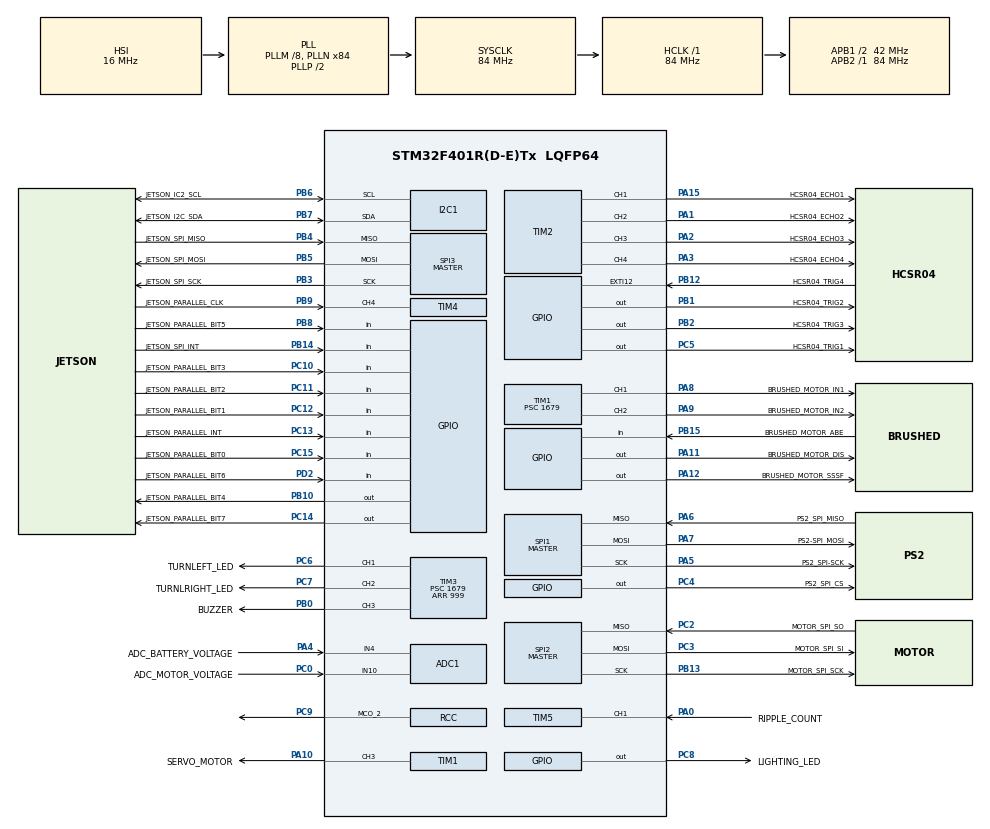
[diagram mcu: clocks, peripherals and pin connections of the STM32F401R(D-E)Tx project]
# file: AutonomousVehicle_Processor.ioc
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ADC1.Channel-0\#ChannelRegularConversion=ADC_CHANNEL_4
ADC1.NbrOfConversionFlag=1
ADC1.Rank-0\#ChannelRegularConversion=1
ADC1.SamplingTime-0\#ChannelRegularConversion=ADC_SAMPLETIME_3CYCLES
ADC1.master=1
FREERTOS.Tasks01=defaultTask,0,128,StartDefaultTask,Default,NULL,Dynamic,NULL,NULL
Mcu.Family=STM32F4
Mcu.Name=STM32F401R(D-E)Tx
Mcu.Package=LQFP64
NVIC.PriorityGroup=NVIC_PRIORITYGROUP_4
PA0-WKUP.GPIO_Label=RIPPLE_COUNT
PA0-WKUP.Signal=S_TIM5_CH1
PA1.GPIO_Label=HCSR04_ECHO2
PA1.Signal=S_TIM2_CH2
PA10.GPIO_Label=SERVO_MOTOR
PA10.Signal=S_TIM1_CH3
PA11.GPIO_Label=BRUSHED_MOTOR_DIS
PA11.Signal=GPIO_Output
PA12.GPIO_Label=BRUSHED_MOTOR_SSSF
PA12.Signal=GPIO_Output
PA13.Mode=Serial_Wire
PA13.Signal=SYS_JTMS-SWDIO
PA14.Mode=Serial_Wire
PA14.Signal=SYS_JTCK-SWCLK
PA15.GPIO_Label=HCSR04_ECHO1
PA15.Signal=S_TIM2_CH1_ETR
PA2.GPIO_Label=HCSR04_ECHO3
PA2.Signal=S_TIM2_CH3
PA3.GPIO_Label=HCSR04_ECHO4
PA3.Signal=S_TIM2_CH4
PA4.GPIO_Label=ADC_BATTERY_VOLTAGE
PA4.Signal=ADCx_IN4
PA5.GPIO_Label=PS2_SPI-SCK
PA5.Mode=Full_Duplex_Master
PA5.Signal=SPI1_SCK
PA6.GPIO_Label=PS2_SPI_MISO
PA6.Mode=Full_Duplex_Master
PA6.Signal=SPI1_MISO
PA7.GPIO_Label=PS2-SPI_MOSI
PA7.Mode=Full_Duplex_Master
PA7.Signal=SPI1_MOSI
PA8.GPIO_Label=BRUSHED_MOTOR_IN1
PA8.Signal=S_TIM1_CH1
PA9.GPIO_Label=BRUSHED_MOTOR_IN2
PA9.Signal=S_TIM1_CH2
PB0.GPIO_Label=BUZZER
PB0.Signal=S_TIM3_CH3
PB1.GPIO_Label=HCSR04_TRIG2
PB1.Signal=GPIO_Output
PB10.GPIO_Label=JETSON_PARALLEL_BIT4
PB10.Signal=GPIO_Output
PB12.GPIO_Label=HCSR04_TRIG4
PB12.Signal=GPXTI12
PB13.GPIO_Label=MOTOR_SPI_SCK
PB13.Mode=Full_Duplex_Master
PB13.Signal=SPI2_SCK
PB14.GPIO_Label=JETSON_SPI_INT
PB14.Signal=GPIO_Input
PB15.GPIO_Label=BRUSHED_MOTOR_ABE
PB15.Signal=GPIO_Input
PB2.GPIO_Label=HCSR04_TRIG3
PB2.Signal=GPIO_Output
PB3.GPIO_Label=JETSON_SPI_SCK
PB3.Mode=Full_Duplex_Master
PB3.Signal=SPI3_SCK
PB4.GPIO_Label=JETSON_SPI_MISO
PB4.Mode=Full_Duplex_Master
PB4.Signal=SPI3_MISO
PB5.GPIO_Label=JETSON_SPI_MOSI
PB5.Mode=Full_Duplex_Master
PB5.Signal=SPI3_MOSI
PB6.GPIO_Label=JETSON_IC2_SCL
PB6.Mode=I2C
PB6.Signal=I2C1_SCL
PB7.GPIO_Label=JETSON_I2C_SDA
PB7.Mode=I2C
PB7.Signal=I2C1_SDA
PB8.GPIO_Label=JETSON_PARALLEL_BIT5
PB8.Signal=GPIO_Input
PB9.GPIO_Label=JETSON_PARALLEL_CLK
PB9.Signal=S_TIM4_CH4
PC0.GPIO_Label=ADC_MOTOR_VOLTAGE
PC0.Signal=ADCx_IN10
PC10.GPIO_Label=JETSON_PARALLEL_BIT3
PC10.Signal=GPIO_Input
PC11.GPIO_Label=JETSON_PARALLEL_BIT2
PC11.Signal=GPIO_Input
PC12.GPIO_Label=JETSON_PARALLEL_BIT1
PC12.Signal=GPIO_Input
PC13-ANTI_TAMP.GPIO_Label=JETSON_PARALLEL_INT
PC13-ANTI_TAMP.Signal=GPIO_Input
PC14-OSC32_IN.GPIO_Label=JETSON_PARALLEL_BIT7
PC14-OSC32_IN.Signal=GPIO_Output
PC15-OSC32_OUT.GPIO_Label=JETSON_PARALLEL_BIT0
PC15-OSC32_OUT.Signal=GPIO_Input
PC2.GPIO_Label=MOTOR_SPI_SO
PC2.Mode=Full_Duplex_Master
PC2.Signal=SPI2_MISO
PC3.GPIO_Label=MOTOR_SPI_SI
PC3.Mode=Full_Duplex_Master
PC3.Signal=SPI2_MOSI
PC4.GPIO_Label=PS2_SPI_CS
PC4.Signal=GPIO_Output
PC5.GPIO_Label=HCSR04_TRIG1
PC5.Signal=GPIO_Output
PC6.GPIO_Label=TURNLEFT_LED
PC6.Signal=S_TIM3_CH1
PC7.GPIO_Label=TURNLRIGHT_LED
PC7.Signal=S_TIM3_CH2
PC8.GPIO_Label=LIGHTING_LED
PC8.Signal=GPIO_Output
PC9.Mode=Clock-out-2
PC9.Signal=RCC_MCO_2
PD2.GPIO_Label=JETSON_PARALLEL_BIT6
PD2.Signal=GPIO_Input
PH0\ -\ OSC_IN.Mode=HSE-External-Oscillator
PH0\ -\ OSC_IN.Signal=RCC_OSC_IN
PH1\ -\ OSC_OUT.Mode=HSE-External-Oscillator
PH1\ -\ OSC_OUT.Signal=RCC_OSC_OUT
ProjectManager.HeapSize=0x200
ProjectManager.StackSize=0x400
ProjectManager.TargetToolchain=STM32CubeIDE
RCC.48MHZClocksFreq_Value=42000000
RCC.AHBFreq_Value=84000000
RCC.APB1CLKDivider=RCC_HCLK_DIV2
RCC.APB1Freq_Value=42000000
RCC.APB1TimFreq_Value=84000000
RCC.APB2Freq_Value=84000000
RCC.APB2TimFreq_Value=84000000
RCC.CortexFreq_Value=84000000
RCC.HCLKFreq_Value=84000000
RCC.HSE_VALUE=25000000
RCC.HSI_VALUE=16000000
RCC.LSE_VALUE=32768
RCC.PLLM=8
RCC.PLLN=84
RCC.SYSCLKFreq_VALUE=84000000
RCC.SYSCLKSource=RCC_SYSCLKSOURCE_PLLCLK
RCC.VCOOutputFreq_Value=168000000
SH.ADCx_IN10.0=ADC1_IN10,IN10
SH.ADCx_IN4.0=ADC1_IN4,IN4
SH.S_TIM1_CH1.0=TIM1_CH1,PWM Generation1 CH1
SH.S_TIM1_CH2.0=TIM1_CH2,PWM Generation2 CH2
SH.S_TIM1_CH3.0=TIM1_CH3,PWM Generation3 CH3
SH.S_TIM2_CH1_ETR.0=TIM2_CH1,PWM Generation1 CH1
SH.S_TIM2_CH2.0=TIM2_CH2,PWM Generation2 CH2
SH.S_TIM2_CH3.0=TIM2_CH3,PWM Generation3 CH3
SH.S_TIM2_CH4.0=TIM2_CH4,PWM Generation4 CH4
SH.S_TIM3_CH1.0=TIM3_CH1,PWM Generation1 CH1
SH.S_TIM3_CH2.0=TIM3_CH2,PWM Generation2 CH2
SH.S_TIM3_CH3.0=TIM3_CH3,PWM Generation3 CH3
SH.S_TIM4_CH4.0=TIM4_CH4,Input_Capture4_from_TI4
SH.S_TIM5_CH1.0=TIM5_CH1,Input_Capture1_from_TI1
SPI1.Direction=SPI_DIRECTION_2LINES
SPI1.Mode=SPI_MODE_MASTER
SPI1.VirtualType=VM_MASTER
SPI2.Direction=SPI_DIRECTION_2LINES
SPI2.Mode=SPI_MODE_MASTER
SPI2.VirtualType=VM_MASTER
SPI3.Direction=SPI_DIRECTION_2LINES
SPI3.Mode=SPI_MODE_MASTER
SPI3.VirtualType=VM_MASTER
TIM1.Channel-PWM\ Generation1\ CH1=TIM_CHANNEL_1
TIM1.Channel-PWM\ Generation2\ CH2=TIM_CHANNEL_2
TIM1.Channel-PWM\ Generation3\ CH3=TIM_CHANNEL_3
TIM1.Period=999
TIM1.Prescaler=1679
TIM2.Channel-PWM\ Generation1\ CH1=TIM_CHANNEL_1
TIM2.Channel-PWM\ Generation2\ CH2=TIM_CHANNEL_2
TIM2.Channel-PWM\ Generation3\ CH3=TIM_CHANNEL_3
TIM2.Channel-PWM\ Generation4\ CH4=TIM_CHANNEL_4
TIM3.Channel-PWM\ Generation1\ CH1=TIM_CHANNEL_1
TIM3.Channel-PWM\ Generation2\ CH2=TIM_CHANNEL_2
TIM3.Channel-PWM\ Generation3\ CH3=TIM_CHANNEL_3
TIM3.Period=999
TIM3.Prescaler=1679
TIM4.Channel-Input_Capture4_from_TI4=TIM_CHANNEL_4
TIM5.Channel-Input_Capture1_from_TI1=TIM_CHANNEL_1
TIM5.Period=999
TIM5.Prescaler=1679
VP_FREERTOS_VS_CMSIS_V1.Mode=CMSIS_V1
board=custom

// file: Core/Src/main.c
/* USER CODE BEGIN Header */
/**
  ******************************************************************************
  * @file           : main.c
  * @brief          : Main program body
  ******************************************************************************
  * @attention
  *
  * Copyright (c) 2024 STMicroelectronics.
  * All rights reserved.
  *
  * This software is licensed under terms that can be found in the LICENSE file
  * in the root directory of this software component.
  * If no LICENSE file comes with this software, it is provided AS-IS.
  *
  ******************************************************************************
  */
/* USER CODE END Header */
#include "main.h"
#include "cmsis_os.h"

/* USER CODE BEGIN Includes */

// Drivers
#include "Auxiliary_System/Buzzer_System.h"
#include "Auxiliary_System/Lighting_System.h"
#include "Brushed_DC_Motor/Brushed_DC_Motor.h"
#include "Servo_Motor/Servo_Motor.h"
#include "Ripple_Current_Counter/Ripple_Current_Counter.h"
#include "Voltage_Measure/Voltage_Measure.h"

// Applications
#include "Auxiliary_Control/Auxiliary_Control.h"
#include "Brushed_Motor_Diagnosis/Motor_Diagnosis.h"
#include "Speeding_Control/Speeding_Control.h"
#include "Steering_Control/Steering_Control.h"
#include "PS2_Control/PS2_Control.h"
/* USER CODE END Includes */

ADC_HandleTypeDef hadc1;

I2C_HandleTypeDef hi2c1;

SPI_HandleTypeDef hspi1;
SPI_HandleTypeDef hspi2;
SPI_HandleTypeDef hspi3;

TIM_HandleTypeDef htim1;
TIM_HandleTypeDef htim2;
TIM_HandleTypeDef htim3;
TIM_HandleTypeDef htim4;
TIM_HandleTypeDef htim5;

osThreadId defaultTaskHandle;

void SystemClock_Config(void);
static void MX_GPIO_Init(void);
static void MX_ADC1_Init(void);
static void MX_SPI1_Init(void);
static void MX_SPI2_Init(void);
static void MX_TIM1_Init(void);
static void MX_TIM2_Init(void);
static void MX_TIM3_Init(void);
static void MX_TIM5_Init(void);
static void MX_TIM4_Init(void);
static void MX_I2C1_Init(void);
static void MX_SPI3_Init(void);
void StartDefaultTask(void const * argument);

int main(void)
{

  /* MCU Configuration--------------------------------------------------------*/

  /* Reset of all peripherals, Initializes the Flash interface and the Systick. */
  HAL_Init();

  /* Configure the system clock */
  SystemClock_Config();

  /* Initialize all configured peripherals */
  MX_GPIO_Init();
  MX_ADC1_Init();
  MX_SPI1_Init();
  MX_SPI2_Init();
  MX_TIM1_Init();
  MX_TIM2_Init();
  MX_TIM3_Init();
  MX_TIM5_Init();
  MX_TIM4_Init();
  MX_I2C1_Init();
  MX_SPI3_Init();

  /* Create the thread(s) */
  /* definition and creation of defaultTask */
  osThreadDef(defaultTask, StartDefaultTask, osPriorityNormal, 0, 128);
  defaultTaskHandle = osThreadCreate(osThread(defaultTask), NULL);

  /* Start scheduler */
  osKernelStart();

  /* We should never get here as control is now taken by the scheduler */
  /* Infinite loop */
  while (1)
  {

  }
}

void SystemClock_Config(void)
{
  RCC_OscInitTypeDef RCC_OscInitStruct = {0};
  RCC_ClkInitTypeDef RCC_ClkInitStruct = {0};

  /** Configure the main internal regulator output voltage
  */
  __HAL_RCC_PWR_CLK_ENABLE();
  __HAL_PWR_VOLTAGESCALING_CONFIG(PWR_REGULATOR_VOLTAGE_SCALE2);

  /** Initializes the RCC Oscillators according to the specified parameters
  * in the RCC_OscInitTypeDef structure.
  */
  RCC_OscInitStruct.OscillatorType = RCC_OSCILLATORTYPE_HSI;
  RCC_OscInitStruct.HSIState = RCC_HSI_ON;
  RCC_OscInitStruct.HSICalibrationValue = RCC_HSICALIBRATION_DEFAULT;
  RCC_OscInitStruct.PLL.PLLState = RCC_PLL_ON;
  RCC_OscInitStruct.PLL.PLLSource = RCC_PLLSOURCE_HSI;
  RCC_OscInitStruct.PLL.PLLM = 8;
  RCC_OscInitStruct.PLL.PLLN = 84;
  RCC_OscInitStruct.PLL.PLLP = RCC_PLLP_DIV2;
  RCC_OscInitStruct.PLL.PLLQ = 4;
  if (HAL_RCC_OscConfig(&RCC_OscInitStruct) != HAL_OK)
  {
    Error_Handler();
  }

  /** Initializes the CPU, AHB and APB buses clocks
  */
  RCC_ClkInitStruct.ClockType = RCC_CLOCKTYPE_HCLK|RCC_CLOCKTYPE_SYSCLK
                              |RCC_CLOCKTYPE_PCLK1|RCC_CLOCKTYPE_PCLK2;
  RCC_ClkInitStruct.SYSCLKSource = RCC_SYSCLKSOURCE_PLLCLK;
  RCC_ClkInitStruct.AHBCLKDivider = RCC_SYSCLK_DIV1;
  RCC_ClkInitStruct.APB1CLKDivider = RCC_HCLK_DIV2;
  RCC_ClkInitStruct.APB2CLKDivider = RCC_HCLK_DIV1;

  if (HAL_RCC_ClockConfig(&RCC_ClkInitStruct, FLASH_LATENCY_2) != HAL_OK)
  {
    Error_Handler();
  }
  HAL_RCC_MCOConfig(RCC_MCO2, RCC_MCO2SOURCE_SYSCLK, RCC_MCODIV_1);
}

static void MX_ADC1_Init(void)
{

  ADC_ChannelConfTypeDef sConfig = {0};

  /** Configure the global features of the ADC (Clock, Resolution, Data Alignment and number of conversion)
  */
  hadc1.Instance = ADC1;
  hadc1.Init.ClockPrescaler = ADC_CLOCK_SYNC_PCLK_DIV4;
  hadc1.Init.Resolution = ADC_RESOLUTION_12B;
  hadc1.Init.ScanConvMode = DISABLE;
  hadc1.Init.ContinuousConvMode = DISABLE;
  hadc1.Init.DiscontinuousConvMode = DISABLE;
  hadc1.Init.ExternalTrigConvEdge = ADC_EXTERNALTRIGCONVEDGE_NONE;
  hadc1.Init.ExternalTrigConv = ADC_SOFTWARE_START;
  hadc1.Init.DataAlign = ADC_DATAALIGN_RIGHT;
  hadc1.Init.NbrOfConversion = 1;
  hadc1.Init.DMAContinuousRequests = DISABLE;
  hadc1.Init.EOCSelection = ADC_EOC_SINGLE_CONV;
  if (HAL_ADC_Init(&hadc1) != HAL_OK)
  {
    Error_Handler();
  }

  /** Configure for the selected ADC regular channel its corresponding rank in the sequencer and its sample time.
  */
  sConfig.Channel = ADC_CHANNEL_4;
  sConfig.Rank = 1;
  sConfig.SamplingTime = ADC_SAMPLETIME_3CYCLES;
  if (HAL_ADC_ConfigChannel(&hadc1, &sConfig) != HAL_OK)
  {
    Error_Handler();
  }

}

static void MX_I2C1_Init(void)
{

  hi2c1.Instance = I2C1;
  hi2c1.Init.ClockSpeed = 100000;
  hi2c1.Init.DutyCycle = I2C_DUTYCYCLE_2;
  hi2c1.Init.OwnAddress1 = 0;
  hi2c1.Init.AddressingMode = I2C_ADDRESSINGMODE_7BIT;
  hi2c1.Init.DualAddressMode = I2C_DUALADDRESS_DISABLE;
  hi2c1.Init.OwnAddress2 = 0;
  hi2c1.Init.GeneralCallMode = I2C_GENERALCALL_DISABLE;
  hi2c1.Init.NoStretchMode = I2C_NOSTRETCH_DISABLE;
  if (HAL_I2C_Init(&hi2c1) != HAL_OK)
  {
    Error_Handler();
  }

}

static void MX_SPI1_Init(void)
{

  /* SPI1 parameter configuration*/
  hspi1.Instance = SPI1;
  hspi1.Init.Mode = SPI_MODE_MASTER;
  hspi1.Init.Direction = SPI_DIRECTION_2LINES;
  hspi1.Init.DataSize = SPI_DATASIZE_8BIT;
  hspi1.Init.CLKPolarity = SPI_POLARITY_LOW;
  hspi1.Init.CLKPhase = SPI_PHASE_1EDGE;
  hspi1.Init.NSS = SPI_NSS_SOFT;
  hspi1.Init.BaudRatePrescaler = SPI_BAUDRATEPRESCALER_2;
  hspi1.Init.FirstBit = SPI_FIRSTBIT_MSB;
  hspi1.Init.TIMode = SPI_TIMODE_DISABLE;
  hspi1.Init.CRCCalculation = SPI_CRCCALCULATION_DISABLE;
  hspi1.Init.CRCPolynomial = 10;
  if (HAL_SPI_Init(&hspi1) != HAL_OK)
  {
    Error_Handler();
  }

}

static void MX_SPI2_Init(void)
{

  /* SPI2 parameter configuration*/
  hspi2.Instance = SPI2;
  hspi2.Init.Mode = SPI_MODE_MASTER;
  hspi2.Init.Direction = SPI_DIRECTION_2LINES;
  hspi2.Init.DataSize = SPI_DATASIZE_8BIT;
  hspi2.Init.CLKPolarity = SPI_POLARITY_LOW;
  hspi2.Init.CLKPhase = SPI_PHASE_1EDGE;
  hspi2.Init.NSS = SPI_NSS_SOFT;
  hspi2.Init.BaudRatePrescaler = SPI_BAUDRATEPRESCALER_2;
  hspi2.Init.FirstBit = SPI_FIRSTBIT_MSB;
  hspi2.Init.TIMode = SPI_TIMODE_DISABLE;
  hspi2.Init.CRCCalculation = SPI_CRCCALCULATION_DISABLE;
  hspi2.Init.CRCPolynomial = 10;
  if (HAL_SPI_Init(&hspi2) != HAL_OK)
  {
    Error_Handler();
  }

}

static void MX_SPI3_Init(void)
{

  /* SPI3 parameter configuration*/
  hspi3.Instance = SPI3;
  hspi3.Init.Mode = SPI_MODE_MASTER;
  hspi3.Init.Direction = SPI_DIRECTION_2LINES;
  hspi3.Init.DataSize = SPI_DATASIZE_8BIT;
  hspi3.Init.CLKPolarity = SPI_POLARITY_LOW;
  hspi3.Init.CLKPhase = SPI_PHASE_1EDGE;
  hspi3.Init.NSS = SPI_NSS_SOFT;
  hspi3.Init.BaudRatePrescaler = SPI_BAUDRATEPRESCALER_2;
  hspi3.Init.FirstBit = SPI_FIRSTBIT_MSB;
  hspi3.Init.TIMode = SPI_TIMODE_DISABLE;
  hspi3.Init.CRCCalculation = SPI_CRCCALCULATION_DISABLE;
  hspi3.Init.CRCPolynomial = 10;
  if (HAL_SPI_Init(&hspi3) != HAL_OK)
  {
    Error_Handler();
  }

}

static void MX_TIM1_Init(void)
{

  TIM_MasterConfigTypeDef sMasterConfig = {0};
  TIM_OC_InitTypeDef sConfigOC = {0};
  TIM_BreakDeadTimeConfigTypeDef sBreakDeadTimeConfig = {0};

  htim1.Instance = TIM1;
  htim1.Init.Prescaler = 1679;
  htim1.Init.CounterMode = TIM_COUNTERMODE_UP;
  htim1.Init.Period = 999;
  htim1.Init.ClockDivision = TIM_CLOCKDIVISION_DIV1;
  htim1.Init.RepetitionCounter = 0;
  htim1.Init.AutoReloadPreload = TIM_AUTORELOAD_PRELOAD_DISABLE;
  if (HAL_TIM_PWM_Init(&htim1) != HAL_OK)
  {
    Error_Handler();
  }
  sMasterConfig.MasterOutputTrigger = TIM_TRGO_RESET;
  sMasterConfig.MasterSlaveMode = TIM_MASTERSLAVEMODE_DISABLE;
  if (HAL_TIMEx_MasterConfigSynchronization(&htim1, &sMasterConfig) != HAL_OK)
  {
    Error_Handler();
  }
  sConfigOC.OCMode = TIM_OCMODE_PWM1;
  sConfigOC.Pulse = 0;
  sConfigOC.OCPolarity = TIM_OCPOLARITY_HIGH;
  sConfigOC.OCNPolarity = TIM_OCNPOLARITY_HIGH;
  sConfigOC.OCFastMode = TIM_OCFAST_DISABLE;
  sConfigOC.OCIdleState = TIM_OCIDLESTATE_RESET;
  sConfigOC.OCNIdleState = TIM_OCNIDLESTATE_RESET;
  if (HAL_TIM_PWM_ConfigChannel(&htim1, &sConfigOC, TIM_CHANNEL_1) != HAL_OK)
  {
    Error_Handler();
  }
  if (HAL_TIM_PWM_ConfigChannel(&htim1, &sConfigOC, TIM_CHANNEL_2) != HAL_OK)
  {
    Error_Handler();
  }
  if (HAL_TIM_PWM_ConfigChannel(&htim1, &sConfigOC, TIM_CHANNEL_3) != HAL_OK)
  {
    Error_Handler();
  }
  sBreakDeadTimeConfig.OffStateRunMode = TIM_OSSR_DISABLE;
  sBreakDeadTimeConfig.OffStateIDLEMode = TIM_OSSI_DISABLE;
  sBreakDeadTimeConfig.LockLevel = TIM_LOCKLEVEL_OFF;
  sBreakDeadTimeConfig.DeadTime = 0;
  sBreakDeadTimeConfig.BreakState = TIM_BREAK_DISABLE;
  sBreakDeadTimeConfig.BreakPolarity = TIM_BREAKPOLARITY_HIGH;
  sBreakDeadTimeConfig.AutomaticOutput = TIM_AUTOMATICOUTPUT_DISABLE;
  if (HAL_TIMEx_ConfigBreakDeadTime(&htim1, &sBreakDeadTimeConfig) != HAL_OK)
  {
    Error_Handler();
  }
  HAL_TIM_MspPostInit(&htim1);

}

static void MX_TIM2_Init(void)
{

  TIM_MasterConfigTypeDef sMasterConfig = {0};
  TIM_OC_InitTypeDef sConfigOC = {0};

  htim2.Instance = TIM2;
  htim2.Init.Prescaler = 0;
  htim2.Init.CounterMode = TIM_COUNTERMODE_UP;
  htim2.Init.Period = 4294967295;
  htim2.Init.ClockDivision = TIM_CLOCKDIVISION_DIV1;
  htim2.Init.AutoReloadPreload = TIM_AUTORELOAD_PRELOAD_DISABLE;
  if (HAL_TIM_PWM_Init(&htim2) != HAL_OK)
  {
    Error_Handler();
  }
  sMasterConfig.MasterOutputTrigger = TIM_TRGO_RESET;
  sMasterConfig.MasterSlaveMode = TIM_MASTERSLAVEMODE_DISABLE;
  if (HAL_TIMEx_MasterConfigSynchronization(&htim2, &sMasterConfig) != HAL_OK)
  {
    Error_Handler();
  }
  sConfigOC.OCMode = TIM_OCMODE_PWM1;
  sConfigOC.Pulse = 0;
  sConfigOC.OCPolarity = TIM_OCPOLARITY_HIGH;
  sConfigOC.OCFastMode = TIM_OCFAST_DISABLE;
  if (HAL_TIM_PWM_ConfigChannel(&htim2, &sConfigOC, TIM_CHANNEL_1) != HAL_OK)
  {
    Error_Handler();
  }
  if (HAL_TIM_PWM_ConfigChannel(&htim2, &sConfigOC, TIM_CHANNEL_2) != HAL_OK)
  {
    Error_Handler();
  }
  if (HAL_TIM_PWM_ConfigChannel(&htim2, &sConfigOC, TIM_CHANNEL_3) != HAL_OK)
  {
    Error_Handler();
  }
  if (HAL_TIM_PWM_ConfigChannel(&htim2, &sConfigOC, TIM_CHANNEL_4) != HAL_OK)
  {
    Error_Handler();
  }
  HAL_TIM_MspPostInit(&htim2);

}

static void MX_TIM3_Init(void)
{

  TIM_MasterConfigTypeDef sMasterConfig = {0};
  TIM_OC_InitTypeDef sConfigOC = {0};

  htim3.Instance = TIM3;
  htim3.Init.Prescaler = 1679;
  htim3.Init.CounterMode = TIM_COUNTERMODE_UP;
  htim3.Init.Period = 999;
  htim3.Init.ClockDivision = TIM_CLOCKDIVISION_DIV1;
  htim3.Init.AutoReloadPreload = TIM_AUTORELOAD_PRELOAD_DISABLE;
  if (HAL_TIM_PWM_Init(&htim3) != HAL_OK)
  {
    Error_Handler();
  }
  sMasterConfig.MasterOutputTrigger = TIM_TRGO_RESET;
  sMasterConfig.MasterSlaveMode = TIM_MASTERSLAVEMODE_DISABLE;
  if (HAL_TIMEx_MasterConfigSynchronization(&htim3, &sMasterConfig) != HAL_OK)
  {
    Error_Handler();
  }
  sConfigOC.OCMode = TIM_OCMODE_PWM1;
  sConfigOC.Pulse = 0;
  sConfigOC.OCPolarity = TIM_OCPOLARITY_HIGH;
  sConfigOC.OCFastMode = TIM_OCFAST_DISABLE;
  if (HAL_TIM_PWM_ConfigChannel(&htim3, &sConfigOC, TIM_CHANNEL_1) != HAL_OK)
  {
    Error_Handler();
  }
  if (HAL_TIM_PWM_ConfigChannel(&htim3, &sConfigOC, TIM_CHANNEL_2) != HAL_OK)
  {
    Error_Handler();
  }
  if (HAL_TIM_PWM_ConfigChannel(&htim3, &sConfigOC, TIM_CHANNEL_3) != HAL_OK)
  {
    Error_Handler();
  }
  HAL_TIM_MspPostInit(&htim3);

}

static void MX_TIM4_Init(void)
{

  TIM_MasterConfigTypeDef sMasterConfig = {0};
  TIM_IC_InitTypeDef sConfigIC = {0};

  htim4.Instance = TIM4;
  htim4.Init.Prescaler = 0;
  htim4.Init.CounterMode = TIM_COUNTERMODE_UP;
  htim4.Init.Period = 65535;
  htim4.Init.ClockDivision = TIM_CLOCKDIVISION_DIV1;
  htim4.Init.AutoReloadPreload = TIM_AUTORELOAD_PRELOAD_DISABLE;
  if (HAL_TIM_IC_Init(&htim4) != HAL_OK)
  {
    Error_Handler();
  }
  sMasterConfig.MasterOutputTrigger = TIM_TRGO_RESET;
  sMasterConfig.MasterSlaveMode = TIM_MASTERSLAVEMODE_DISABLE;
  if (HAL_TIMEx_MasterConfigSynchronization(&htim4, &sMasterConfig) != HAL_OK)
  {
    Error_Handler();
  }
  sConfigIC.ICPolarity = TIM_INPUTCHANNELPOLARITY_RISING;
  sConfigIC.ICSelection = TIM_ICSELECTION_DIRECTTI;
  sConfigIC.ICPrescaler = TIM_ICPSC_DIV1;
  sConfigIC.ICFilter = 0;
  if (HAL_TIM_IC_ConfigChannel(&htim4, &sConfigIC, TIM_CHANNEL_4) != HAL_OK)
  {
    Error_Handler();
  }

}

static void MX_TIM5_Init(void)
{

  TIM_MasterConfigTypeDef sMasterConfig = {0};
  TIM_IC_InitTypeDef sConfigIC = {0};

  htim5.Instance = TIM5;
  htim5.Init.Prescaler = 1679;
  htim5.Init.CounterMode = TIM_COUNTERMODE_UP;
  htim5.Init.Period = 999;
  htim5.Init.ClockDivision = TIM_CLOCKDIVISION_DIV1;
  htim5.Init.AutoReloadPreload = TIM_AUTORELOAD_PRELOAD_DISABLE;
  if (HAL_TIM_IC_Init(&htim5) != HAL_OK)
  {
    Error_Handler();
  }
  sMasterConfig.MasterOutputTrigger = TIM_TRGO_RESET;
  sMasterConfig.MasterSlaveMode = TIM_MASTERSLAVEMODE_DISABLE;
  if (HAL_TIMEx_MasterConfigSynchronization(&htim5, &sMasterConfig) != HAL_OK)
  {
    Error_Handler();
  }
  sConfigIC.ICPolarity = TIM_INPUTCHANNELPOLARITY_RISING;
  sConfigIC.ICSelection = TIM_ICSELECTION_DIRECTTI;
  sConfigIC.ICPrescaler = TIM_ICPSC_DIV1;
  sConfigIC.ICFilter = 0;
  if (HAL_TIM_IC_ConfigChannel(&htim5, &sConfigIC, TIM_CHANNEL_1) != HAL_OK)
  {
    Error_Handler();
  }

}

static void MX_GPIO_Init(void)
{
  GPIO_InitTypeDef GPIO_InitStruct = {0};

  /* GPIO Ports Clock Enable */
  __HAL_RCC_GPIOC_CLK_ENABLE();
  __HAL_RCC_GPIOH_CLK_ENABLE();
  __HAL_RCC_GPIOA_CLK_ENABLE();
  __HAL_RCC_GPIOB_CLK_ENABLE();
  __HAL_RCC_GPIOD_CLK_ENABLE();

  /*Configure GPIO pin Output Level */
  HAL_GPIO_WritePin(GPIOC, JETSON_PARALLEL_BIT7_Pin|PS2_SPI_CS_Pin|HCSR04_TRIG1_Pin|LIGHTING_LED_Pin, GPIO_PIN_RESET);

  /*Configure GPIO pin Output Level */
  HAL_GPIO_WritePin(GPIOB, HCSR04_TRIG2_Pin|HCSR04_TRIG3_Pin|JETSON_PARALLEL_BIT4_Pin, GPIO_PIN_RESET);

  /*Configure GPIO pin Output Level */
  HAL_GPIO_WritePin(GPIOA, BRUSHED_MOTOR_DIS_Pin|BRUSHED_MOTOR_SSSF_Pin, GPIO_PIN_RESET);

  /*Configure GPIO pins : JETSON_PARALLEL_INT_Pin JETSON_PARALLEL_BIT0_Pin JETSON_PARALLEL_BIT3_Pin JETSON_PARALLEL_BIT2_Pin
                           JETSON_PARALLEL_BIT1_Pin */
  GPIO_InitStruct.Pin = JETSON_PARALLEL_INT_Pin|JETSON_PARALLEL_BIT0_Pin|JETSON_PARALLEL_BIT3_Pin|JETSON_PARALLEL_BIT2_Pin
                          |JETSON_PARALLEL_BIT1_Pin;
  GPIO_InitStruct.Mode = GPIO_MODE_INPUT;
  GPIO_InitStruct.Pull = GPIO_NOPULL;
  HAL_GPIO_Init(GPIOC, &GPIO_InitStruct);

  /*Configure GPIO pins : JETSON_PARALLEL_BIT7_Pin PS2_SPI_CS_Pin HCSR04_TRIG1_Pin LIGHTING_LED_Pin */
  GPIO_InitStruct.Pin = JETSON_PARALLEL_BIT7_Pin|PS2_SPI_CS_Pin|HCSR04_TRIG1_Pin|LIGHTING_LED_Pin;
  GPIO_InitStruct.Mode = GPIO_MODE_OUTPUT_PP;
  GPIO_InitStruct.Pull = GPIO_NOPULL;
  GPIO_InitStruct.Speed = GPIO_SPEED_FREQ_LOW;
  HAL_GPIO_Init(GPIOC, &GPIO_InitStruct);

  /*Configure GPIO pins : HCSR04_TRIG2_Pin HCSR04_TRIG3_Pin JETSON_PARALLEL_BIT4_Pin */
  GPIO_InitStruct.Pin = HCSR04_TRIG2_Pin|HCSR04_TRIG3_Pin|JETSON_PARALLEL_BIT4_Pin;
  GPIO_InitStruct.Mode = GPIO_MODE_OUTPUT_PP;
  GPIO_InitStruct.Pull = GPIO_NOPULL;
  GPIO_InitStruct.Speed = GPIO_SPEED_FREQ_LOW;
  HAL_GPIO_Init(GPIOB, &GPIO_InitStruct);

  /*Configure GPIO pin : HCSR04_TRIG4_Pin */
  GPIO_InitStruct.Pin = HCSR04_TRIG4_Pin;
  GPIO_InitStruct.Mode = GPIO_MODE_IT_RISING;
  GPIO_InitStruct.Pull = GPIO_NOPULL;
  HAL_GPIO_Init(HCSR04_TRIG4_GPIO_Port, &GPIO_InitStruct);

  /*Configure GPIO pins : JETSON_SPI_INT_Pin BRUSHED_MOTOR_ABE_Pin JETSON_PARALLEL_BIT5_Pin */
  GPIO_InitStruct.Pin = JETSON_SPI_INT_Pin|BRUSHED_MOTOR_ABE_Pin|JETSON_PARALLEL_BIT5_Pin;
  GPIO_InitStruct.Mode = GPIO_MODE_INPUT;
  GPIO_InitStruct.Pull = GPIO_NOPULL;
  HAL_GPIO_Init(GPIOB, &GPIO_InitStruct);

  /*Configure GPIO pin : PC9 */
  GPIO_InitStruct.Pin = GPIO_PIN_9;
  GPIO_InitStruct.Mode = GPIO_MODE_AF_PP;
  GPIO_InitStruct.Pull = GPIO_NOPULL;
  GPIO_InitStruct.Speed = GPIO_SPEED_FREQ_LOW;
  GPIO_InitStruct.Alternate = GPIO_AF0_MCO;
  HAL_GPIO_Init(GPIOC, &GPIO_InitStruct);

  /*Configure GPIO pins : BRUSHED_MOTOR_DIS_Pin BRUSHED_MOTOR_SSSF_Pin */
  GPIO_InitStruct.Pin = BRUSHED_MOTOR_DIS_Pin|BRUSHED_MOTOR_SSSF_Pin;
  GPIO_InitStruct.Mode = GPIO_MODE_OUTPUT_PP;
  GPIO_InitStruct.Pull = GPIO_NOPULL;
  GPIO_InitStruct.Speed = GPIO_SPEED_FREQ_LOW;
  HAL_GPIO_Init(GPIOA, &GPIO_InitStruct);

  /*Configure GPIO pin : JETSON_PARALLEL_BIT6_Pin */
  GPIO_InitStruct.Pin = JETSON_PARALLEL_BIT6_Pin;
  GPIO_InitStruct.Mode = GPIO_MODE_INPUT;
  GPIO_InitStruct.Pull = GPIO_NOPULL;
  HAL_GPIO_Init(JETSON_PARALLEL_BIT6_GPIO_Port, &GPIO_InitStruct);

}

void StartDefaultTask(void const * argument)
{
  for(;;)
  {
    osDelay(1);
  }
}

void Error_Handler(void)
{
  __disable_irq();
  while (1)
  {
  }
}
